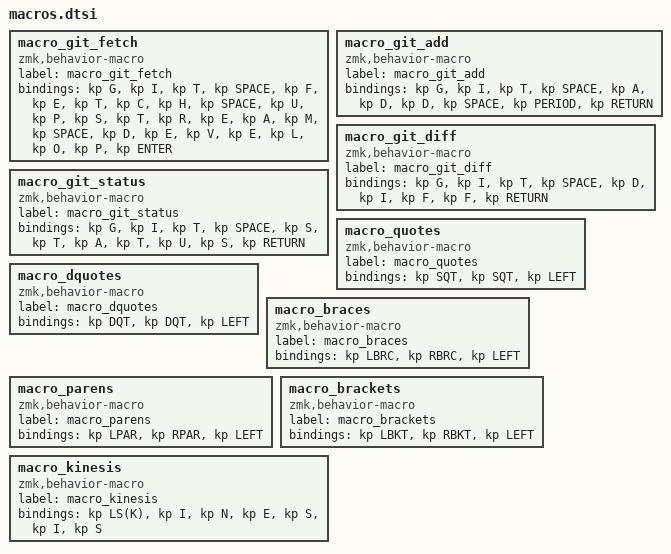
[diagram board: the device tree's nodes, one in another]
macro_git_fetch: macro_git_fetch{
compatible = "zmk,behavior-macro";
label = "macro_git_fetch";
#binding-cells = <0>;
bindings = <&kp G>, <&kp I>, <&kp T>, <&kp SPACE>, <&kp F>, <&kp E>, <&kp T>, <&kp C>, <&kp H>, <&kp SPACE>, <&kp U>, <&kp P>, <&kp S>, <&kp T>, <&kp R>, <&kp E>, <&kp A>, <&kp M>, <&kp SPACE>, <&kp D>, <&kp E>, <&kp V>, <&kp E>, <&kp L>, <&kp O>, <&kp P>, <&kp ENTER>;
};
macro_git_add: macro_git_add{
compatible = "zmk,behavior-macro";
label = "macro_git_add";
#binding-cells = <0>;
bindings = <&kp G>, <&kp I>, <&kp T>, <&kp SPACE>, <&kp A>, <&kp D>, <&kp D>, <&kp SPACE>, <&kp PERIOD>, <&kp RETURN>;
};
macro_git_diff: macro_git_diff{
compatible = "zmk,behavior-macro";
label = "macro_git_diff";
#binding-cells = <0>;
bindings = <&kp G>, <&kp I>, <&kp T>, <&kp SPACE>, <&kp D>, <&kp I>, <&kp F>, <&kp F>, <&kp RETURN>;
};
macro_git_status: macro_git_status{
compatible = "zmk,behavior-macro";
label = "macro_git_status";
#binding-cells = <0>;
bindings = <&kp G>, <&kp I>, <&kp T>, <&kp SPACE>, <&kp S>, <&kp T>, <&kp A>, <&kp T>, <&kp U>, <&kp S>, <&kp RETURN>;
};
macro_quotes: macro_quotes{
compatible = "zmk,behavior-macro";
label = "macro_quotes";
#binding-cells = <0>;
bindings = <&kp SQT>, <&kp SQT>, <&kp LEFT>;
};
macro_dquotes: macro_dquotes{
compatible = "zmk,behavior-macro";
label = "macro_dquotes";
#binding-cells = <0>;
bindings = <&kp DQT>, <&kp DQT>, <&kp LEFT>;
};
macro_braces: macro_braces{
compatible = "zmk,behavior-macro";
label = "macro_braces";
#binding-cells = <0>;
bindings = <&kp LBRC>, <&kp RBRC>, <&kp LEFT>;
};
macro_parens: macro_parens{
compatible = "zmk,behavior-macro";
label = "macro_parens";
#binding-cells = <0>;
bindings = <&kp LPAR>, <&kp RPAR>, <&kp LEFT>;
};
macro_brackets: macro_brackets{
compatible = "zmk,behavior-macro";
label = "macro_brackets";
#binding-cells = <0>;
bindings = <&kp LBKT>, <&kp RBKT>, <&kp LEFT>;
};
macro_kinesis: macro_kinesis{
compatible = "zmk,behavior-macro";
label = "macro_kinesis";
#binding-cells = <0>;
bindings = <&kp LS(K)>, <&kp I>, <&kp N>, <&kp E>, <&kp S>, <&kp I>, <&kp S>;
};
